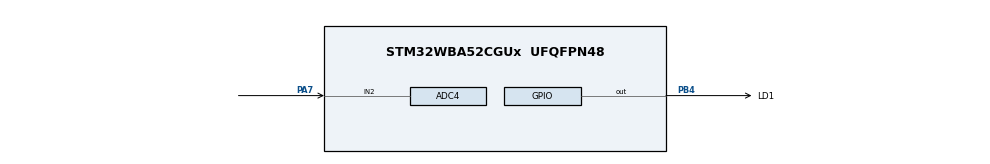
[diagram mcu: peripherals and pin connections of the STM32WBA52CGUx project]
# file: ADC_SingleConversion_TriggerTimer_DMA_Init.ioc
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ADC4.Channel-0\#ChannelRegularConversion=ADC_CHANNEL_2
ADC4.ClockPrescaler=ADC_CLOCK_ASYNC_DIV4
ADC4.DMAContinuousRequests=ENABLE
ADC4.ExternalTrigConv=ADC_EXTERNALTRIG_T1_TRGO2
ADC4.NbrOfConversionFlag=1
ADC4.Overrun=ADC_OVR_DATA_OVERWRITTEN
ADC4.Rank-0\#ChannelRegularConversion=1
ADC4.SamplingTime-0\#ChannelRegularConversion=ADC_SAMPLINGTIME_COMMON_1
ADC4.SelectedChannel=ADC_CHANNEL_2
CORTEX_M33_NS.userName=CORTEX_M33
GPDMA1.CIRCULARMODE_GPDMACH1=ENABLE
GPDMA1.DESTDATAWIDTH_GPDMACH1=DMA_DEST_DATAWIDTH_HALFWORD
GPDMA1.DESTINC_GPDMACH1=DMA_DINC_INCREMENTED
GPDMA1.IPHANDLE_GPDMACH1-SIMPLEREQUEST_GPDMACH1=__NULL
GPDMA1.REQUEST_GPDMACH1=GPDMA1_REQUEST_ADC4
GPDMA1.SRCDATAWIDTH_GPDMACH1=DMA_SRC_DATAWIDTH_HALFWORD
Mcu.Family=STM32WBA
Mcu.Name=STM32WBA52CGUx
Mcu.Package=UFQFPN48
NVIC.ADC4_IRQn=true\:0\:0\:false\:false\:false\:true\:true\:true
NVIC.GPDMA1_Channel1_IRQn=true\:0\:0\:false\:false\:false\:false\:true\:true
NVIC.PriorityGroup=NVIC_PRIORITYGROUP_4
OSC_IN.Mode=HSE-External-Oscillator
OSC_IN.Signal=RCC_OSC_IN
OSC_OUT.Mode=HSE-External-Oscillator
OSC_OUT.Signal=RCC_OSC_OUT
PA7.Mode=IN2
PA7.Signal=ADC4_IN2
PB4\ (NJTRST).GPIO_Label=LD1
PB4\ (NJTRST).PinState=GPIO_PIN_SET
PB4\ (NJTRST).Signal=GPIO_Output
ProjectManager.HeapSize=0x200
ProjectManager.StackSize=0x400
ProjectManager.TargetToolchain=EWARM V9.20
RCC.ADCCLockSelectionVirtual=RCC_ADCCLKSOURCE_HSI
RCC.ADCFreq_Value=16000000
RCC.AHB5CLKDivider=DIV4
RCC.AHBFreq_Value=100000000
RCC.APB1Freq_Value=100000000
RCC.APB1TimFreq_Value=100000000
RCC.APB2Freq_Value=100000000
RCC.APB2TimFreq_Value=100000000
RCC.CortexFreq_Value=12500000
RCC.HCLKFreq_Value=100000000
RCC.HSE_VALUE=32000000
RCC.HSI_VALUE=16000000
RCC.LSE_VALUE=32768
RCC.PLLM=4
RCC.PLLN=25
RCC.PLLSourceVirtual=RCC_PLLSOURCE_HSE
RCC.SYSCLKFreq_VALUE=100000000
RCC.SYSCLKSourceVirtual=RCC_SYSCLKSOURCE_PLLCLK
RCC.VCOOutputFreq_Value=200000000
TIM1.PeriodNoDither=tim_period
TIM1.Prescaler=tim_prescaler
TIM1.TIM_MasterOutputTrigger=TIM_TRGO_RESET
TIM1.TIM_MasterOutputTrigger2=TIM_TRGO2_UPDATE
VP_GPDMA1_VS_GPDMACH1.Mode=SIMPLEREQUEST_GPDMACH1
VP_ICACHE_VS_ICACHE.Mode=DirectMappedCache
VP_PWR_VS_SECSignals.Mode=Security/Privilege
VP_TIM1_VS_ClockSourceINT.Mode=Internal
board=custom

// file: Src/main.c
/* USER CODE BEGIN Header */
/**
  ******************************************************************************
  * @file    Examples_LL/ADC/ADC_SingleConversion_TriggerTimer_DMA_Init/Src/main.c
  * @author  MCD Application Team
  * @brief   This example describes how to use a ADC peripheral to perform
  *          a single ADC conversion of a channel, at each trigger event
  *          from timer.
  *          Conversion data is transferred by DMA into a table in RAM memory,
  *          indefinitely (circular mode).
  *          This example is based on the STM32WBAxx ADC LL API;
  *          Peripheral initialization done using LL unitary services functions.
  ******************************************************************************
  * @attention
  *
  * Copyright (c) 2023 STMicroelectronics.
  * All rights reserved.
  *
  * This software is licensed under terms that can be found in the LICENSE file
  * in the root directory of this software component.
  * If no LICENSE file comes with this software, it is provided AS-IS.
  *
  ******************************************************************************
  */
/* USER CODE END Header */
#include "main.h"

/* USER CODE BEGIN PD */

/* Definitions of ADC hardware constraints delays */
/* Note: Only ADC IP HW delays are defined in ADC LL driver driver,           */
/*       not timeout values:                                                  */
/*       Timeout values for ADC operations are dependent to device clock      */
/*       configuration (system clock versus ADC clock),                       */
/*       and therefore must be defined in user application.                   */
/*       Refer to @ref ADC_LL_EC_HW_DELAYS for description of ADC timeout     */
/*       values definition.                                                   */

  /* Timeout values for ADC operations. */
  /* (calibration, enable settling time, disable settling time, ...)          */
  /* Values defined to be higher than worst cases: low clock frequency,       */
  /* maximum prescalers.                                                      */
  /* Note: ADC channel configuration ready (ADC_CHANNEL_CONF_RDY_TIMEOUT_MS)  */
  /*       is added in CubeMx code section.                                   */
  /* Unit: ms                                                                 */
  #define ADC_CALIBRATION_TIMEOUT_MS       (   1UL)
  #define ADC_ENABLE_TIMEOUT_MS            (   1UL)
  #define ADC_DISABLE_TIMEOUT_MS           (   1UL)
  #define ADC_STOP_CONVERSION_TIMEOUT_MS   (   1UL)
  #define ADC_CONVERSION_TIMEOUT_MS        (4000UL)

  /* Delay between ADC end of calibration and ADC enable.                     */
  /* Delay estimation in CPU cycles: Case of ADC enable done                  */
  /* immediately after ADC calibration, ADC clock setting slow                */
  /* (LL_ADC_CLOCK_ASYNC_DIV32). Use a higher delay if ratio                  */
  /* (CPU clock / ADC clock) is above 32.                                     */
  #define ADC_DELAY_CALIB_ENABLE_CPU_CYCLES  (LL_ADC_DELAY_CALIB_ENABLE_ADC_CYCLES * 32)

/* Definitions of environment analog values */
  /* Value of analog reference voltage (Vref+), connected to analog voltage   */
  /* supply Vdda (unit: mV).                                                  */
  #define VDDA_APPLI                       (3300UL)

/* Definitions of data related to this example */
  /* Definition of ADCx conversions data table size */
  #define ADC_CONVERTED_DATA_BUFFER_SIZE   (  64UL)

  /* Init variable out of expected ADC conversion data range */
  #define VAR_CONVERTED_DATA_INIT_VALUE    (__LL_ADC_DIGITAL_SCALE(LL_ADC_RESOLUTION_12B) + 1)

  /* Parameters of time base (used as ADC conversion trigger) */
  /* Time base frequency (unit: Hz). With a timer 16 bits and time base       */
  /* freq max 32kHz, range is [min=1Hz, max=32kHz].                           */
  #define TIMER_FREQUENCY_HZ               (1000UL)
  /* Time base range frequency maximum (unit: Hz).*/
  /* With a timer 16 bits, minimum frequency will be 1/32000 times this value.*/
  #define TIMER_FREQUENCY_RANGE_MAX_HZ    (32000UL)

/* USER CODE END PD */

LL_DMA_LinkNodeTypeDef Node_GPDMA1_Channel1;

/* USER CODE BEGIN PV */

/* Variables for ADC conversion data */
__IO uint16_t uhADCxConvertedData[ADC_CONVERTED_DATA_BUFFER_SIZE]; /* ADC group regular conversion data (array of data) */

/* Variables for ADC conversion data computation to physical values */
uint16_t uhADCxConvertedData_Voltage_mVolt[ADC_CONVERTED_DATA_BUFFER_SIZE];  /* Value of voltage calculated from ADC conversion data (unit: mV) (array of data) */

/* Variable to report status of DMA transfer of ADC group regular conversions */
/*  0: DMA transfer is not completed                                          */
/*  1: DMA transfer is completed                                              */
/*  2: DMA transfer has not yet been started yet (initial state)              */
__IO uint8_t ubDmaTransferStatus = 2U; /* Variable set into DMA interruption callback */

/* USER CODE END PV */

void SystemClock_Config(void);
static void MX_GPDMA1_Init(void);
static void MX_GPIO_Init(void);
static void MX_ICACHE_Init(void);
static void MX_ADC4_Init(void);
static void MX_TIM1_Init(void);
/* USER CODE BEGIN PFP */

void ADC_Activate(void);
void LED_On(void);
void LED_Off(void);
void LED_Toggle(void);

/* USER CODE END PFP */

int main(void)
{
  /* USER CODE BEGIN 1 */
  uint32_t tmp_index;

  /* Initialize ADC group regular data buffer values */
  for (tmp_index = 0; tmp_index < ADC_CONVERTED_DATA_BUFFER_SIZE; tmp_index++)
  {
    uhADCxConvertedData[tmp_index] = VAR_CONVERTED_DATA_INIT_VALUE;
  }

  /* USER CODE END 1 */

  /* MCU Configuration--------------------------------------------------------*/

  /* Reset of all peripherals, Initializes the Flash interface and the Systick. */

  /* System interrupt init*/
  NVIC_SetPriorityGrouping(NVIC_PRIORITYGROUP_4);

  /* SysTick_IRQn interrupt configuration */
  NVIC_SetPriority(SysTick_IRQn, NVIC_EncodePriority(NVIC_GetPriorityGrouping(),15, 0));

  /* Enable PWR clock interface */

  LL_AHB4_GRP1_EnableClock(LL_AHB4_GRP1_PERIPH_PWR);

  /* Configure the system clock */
  SystemClock_Config();

  /* Initialize all configured peripherals */
  MX_GPDMA1_Init();
  MX_GPIO_Init();
  MX_ICACHE_Init();
  MX_ADC4_Init();
  MX_TIM1_Init();
  /* USER CODE BEGIN 2 */

  /* Activate ADC */
  /* Perform ADC activation procedure to make it ready to convert. */
  ADC_Activate();

  /* Start ADC group regular conversion */
  /* Note: ADC conversion will effectively start at timer trigger event */
  /* Note: Hardware constraint (refer to description of the functions         */
  /*       below):                                                            */
  /*       On this STM32 series, setting of this feature is conditioned to    */
  /*       ADC state:                                                         */
  /*       ADC must be enabled without conversion on going on group regular,  */
  /*       without ADC disable command on going.                              */
  /* Note: In this example, all these checks are not necessary but are        */
  /*       implemented anyway to show the best practice usages                */
  /*       corresponding to reference manual procedure.                       */
  /*       Software can be optimized by removing some of these checks, if     */
  /*       they are not relevant considering previous settings and actions    */
  /*       in user application.                                               */
  if ((LL_ADC_IsEnabled(ADC4) == 1)               &&
      (LL_ADC_IsDisableOngoing(ADC4) == 0)        &&
      (LL_ADC_REG_IsConversionOngoing(ADC4) == 0)   )
  {
    LL_ADC_REG_StartConversion(ADC4);
  }
  else
  {
    /* Error: ADC conversion start could not be performed */
    Error_Handler();
  }

  /* Start time base */
  LL_TIM_EnableCounter(TIM1);

  /* USER CODE END 2 */

  /* Infinite loop */
  /* USER CODE BEGIN WHILE */
  while (1)
  {
    /* ADC group regular status: toggle LED at buffer conversion completed */
    if(ubDmaTransferStatus == 1)
    {
      LED_On();
    }
    else
    {
      LED_Off();
    }

    /* Note: ADC group regular conversions data are stored into array         */
    /*       "uhADCxConvertedData"                                            */
    /*       (for debug: see variable content into watch window).             */

    /* Note: ADC conversion data are computed to physical values              */
    /*       into array "uhADCxConvertedData_Voltage_mVolt" using             */
    /*       ADC LL driver helper macro "__LL_ADC_CALC_DATA_TO_VOLTAGE()"     */
    /*       (for debug: see variable content with debugger)                  */
    /*       in IRQ handlers callback functions.                              */

    /* USER CODE END WHILE */

  }
}

void SystemClock_Config(void)
{
  LL_FLASH_SetLatency(LL_FLASH_LATENCY_3);
  while(LL_FLASH_GetLatency()!= LL_FLASH_LATENCY_3)
  {
  }

  LL_PWR_SetRegulVoltageScaling(LL_PWR_REGU_VOLTAGE_SCALE1);
  LL_RCC_HSE_Enable();

   /* Wait till HSE is ready */
  while(LL_RCC_HSE_IsReady() != 1)
  {
  }

  LL_RCC_HSI_Enable();

   /* Wait till HSI is ready */
  while(LL_RCC_HSI_IsReady() != 1)
  {
  }

  LL_RCC_HSI_SetCalibTrimming(16);
  LL_RCC_PLL1_ConfigDomain_SYS(LL_RCC_PLL1SOURCE_HSE, 4, 25, 2);
  LL_RCC_PLL1_EnableDomain_PLL1R();
  LL_RCC_PLL1_SetVCOInputRange(LL_RCC_PLLINPUTRANGE_8_16);
  LL_RCC_PLL1_Enable();

   /* Wait till PLL is ready */
  while(LL_RCC_PLL1_IsReady() != 1)
  {
  }

  LL_RCC_SetSysClkSource(LL_RCC_SYS_CLKSOURCE_PLL1R);

   /* Wait till System clock is ready */
  while(LL_RCC_GetSysClkSource() != LL_RCC_SYS_CLKSOURCE_STATUS_PLL1R)
  {
  }

  LL_RCC_SetAHBPrescaler(LL_RCC_SYSCLK_DIV_1);
  LL_RCC_SetAHB5Prescaler(LL_RCC_AHB5_DIV_4);
  LL_RCC_SetAPB1Prescaler(LL_RCC_APB1_DIV_1);
  LL_RCC_SetAPB2Prescaler(LL_RCC_APB2_DIV_1);
  LL_RCC_SetAPB7Prescaler(LL_RCC_APB7_DIV_1);

  LL_Init1msTick(100000000);

  LL_SetSystemCoreClock(100000000);
}

static void MX_ADC4_Init(void)
{

  LL_ADC_InitTypeDef ADC_InitStruct = {0};
  LL_ADC_REG_InitTypeDef ADC_REG_InitStruct = {0};

  LL_GPIO_InitTypeDef GPIO_InitStruct = {0};
  LL_DMA_InitNodeTypeDef NodeConfig = {0};
  LL_DMA_InitLinkedListTypeDef DMA_InitLinkedListStruct = {0};

  LL_RCC_SetADCClockSource(LL_RCC_ADC_CLKSOURCE_HSI);

  /* Peripheral clock enable */
  LL_AHB4_GRP1_EnableClock(LL_AHB4_GRP1_PERIPH_ADC4);

  LL_AHB2_GRP1_EnableClock(LL_AHB2_GRP1_PERIPH_GPIOA);
  /**ADC4 GPIO Configuration
  PA7   ------> ADC4_IN2
  */
  GPIO_InitStruct.Pin = LL_GPIO_PIN_7;
  GPIO_InitStruct.Mode = LL_GPIO_MODE_ANALOG;
  GPIO_InitStruct.Pull = LL_GPIO_PULL_NO;
  LL_GPIO_Init(GPIOA, &GPIO_InitStruct);

  /* ADC4 DMA Init */

  /* GPDMA1_REQUEST_ADC4 Init */
  NodeConfig.DestAllocatedPort = LL_DMA_DEST_ALLOCATED_PORT0;
  NodeConfig.DestHWordExchange = LL_DMA_DEST_HALFWORD_PRESERVE;
  NodeConfig.DestByteExchange = LL_DMA_DEST_BYTE_PRESERVE;
  NodeConfig.DestBurstLength = 1;
  NodeConfig.DestIncMode = LL_DMA_DEST_INCREMENT;
  NodeConfig.DestDataWidth = LL_DMA_DEST_DATAWIDTH_HALFWORD;
  NodeConfig.SrcAllocatedPort = LL_DMA_SRC_ALLOCATED_PORT0;
  NodeConfig.SrcByteExchange = LL_DMA_SRC_BYTE_PRESERVE;
  NodeConfig.DataAlignment = LL_DMA_DATA_ALIGN_ZEROPADD;
  NodeConfig.SrcBurstLength = 1;
  NodeConfig.SrcIncMode = LL_DMA_SRC_FIXED;
  NodeConfig.SrcDataWidth = LL_DMA_SRC_DATAWIDTH_HALFWORD;
  NodeConfig.TransferEventMode = LL_DMA_TCEM_BLK_TRANSFER;
  NodeConfig.TriggerPolarity = LL_DMA_TRIG_POLARITY_MASKED;
  NodeConfig.BlkHWRequest = LL_DMA_HWREQUEST_SINGLEBURST;
  NodeConfig.Direction = LL_DMA_DIRECTION_PERIPH_TO_MEMORY;
  NodeConfig.Request = LL_GPDMA1_REQUEST_ADC4;
  NodeConfig.UpdateRegisters = (LL_DMA_UPDATE_CTR1 | LL_DMA_UPDATE_CTR2 | LL_DMA_UPDATE_CBR1 | LL_DMA_UPDATE_CSAR | LL_DMA_UPDATE_CDAR | LL_DMA_UPDATE_CLLR);
  NodeConfig.NodeType = LL_DMA_GPDMA_LINEAR_NODE;
  LL_DMA_CreateLinkNode(&NodeConfig, &Node_GPDMA1_Channel1);

  LL_DMA_ConnectLinkNode(&Node_GPDMA1_Channel1, LL_DMA_CLLR_OFFSET5, &Node_GPDMA1_Channel1, LL_DMA_CLLR_OFFSET5);

  /* Next function call is commented because it will not compile as is. The Node structure address has to be cast to an unsigned int (uint32_t)pNode_DMAxCHy */
  /*

  */
  LL_DMA_SetLinkedListBaseAddr(GPDMA1, LL_DMA_CHANNEL_1, (uint32_t)&Node_GPDMA1_Channel1);

  DMA_InitLinkedListStruct.Priority = LL_DMA_LOW_PRIORITY_LOW_WEIGHT;
  DMA_InitLinkedListStruct.LinkStepMode = LL_DMA_LSM_FULL_EXECUTION;
  DMA_InitLinkedListStruct.LinkAllocatedPort = LL_DMA_LINK_ALLOCATED_PORT0;
  DMA_InitLinkedListStruct.TransferEventMode = LL_DMA_TCEM_BLK_TRANSFER;
  LL_DMA_List_Init(GPDMA1, LL_DMA_CHANNEL_1, &DMA_InitLinkedListStruct);

  /* ADC4 interrupt Init */
  NVIC_SetPriority(ADC4_IRQn, NVIC_EncodePriority(NVIC_GetPriorityGrouping(),0, 0));
  NVIC_EnableIRQ(ADC4_IRQn);

  /* USER CODE BEGIN ADC4_Init 1 */
  LL_DMA_SetBlkDataLength(GPDMA1,
                          LL_DMA_CHANNEL_1,
                          ADC_CONVERTED_DATA_BUFFER_SIZE);
  LL_DMA_ConfigAddresses(GPDMA1,
                         LL_DMA_CHANNEL_1,
                         LL_ADC_DMA_GetRegAddr(ADC4, LL_ADC_DMA_REG_REGULAR_DATA),
                         (uint32_t)&uhADCxConvertedData);

  /* Enable GPDMA1 interrupts complete/error */
  LL_DMA_EnableIT_TC(GPDMA1, LL_DMA_CHANNEL_1);
  LL_DMA_EnableIT_HT(GPDMA1, LL_DMA_CHANNEL_1);
  LL_DMA_EnableIT_DTE(GPDMA1, LL_DMA_CHANNEL_1);

  LL_DMA_SetLinkedListAddrOffset(GPDMA1, LL_DMA_CHANNEL_1, LL_DMA_CLLR_OFFSET5);

  LL_DMA_EnableChannel(GPDMA1, LL_DMA_CHANNEL_1);
  /* USER CODE END ADC4_Init 1 */

  /** Common config
  */
  LL_ADC_SetTriggerFrequencyMode(ADC4, LL_ADC_TRIGGER_FREQ_LOW);
  ADC_InitStruct.Resolution = LL_ADC_RESOLUTION_12B;
  ADC_InitStruct.DataAlignment = LL_ADC_DATA_ALIGN_RIGHT;
  LL_ADC_Init(ADC4, &ADC_InitStruct);
  LL_ADC_REG_SetSequencerConfigurable(ADC4, LL_ADC_REG_SEQ_CONFIGURABLE);
  ADC_REG_InitStruct.TriggerSource = LL_ADC_REG_TRIG_EXT_TIM1_TRGO2;
  ADC_REG_InitStruct.SequencerLength = LL_ADC_REG_SEQ_SCAN_DISABLE;
  ADC_REG_InitStruct.SequencerDiscont = LL_ADC_REG_SEQ_DISCONT_DISABLE;
  ADC_REG_InitStruct.ContinuousMode = LL_ADC_REG_CONV_SINGLE;
  ADC_REG_InitStruct.DMATransfer = LL_ADC_REG_DMA_TRANSFER_UNLIMITED;
  ADC_REG_InitStruct.Overrun = LL_ADC_REG_OVR_DATA_OVERWRITTEN;
  LL_ADC_REG_Init(ADC4, &ADC_REG_InitStruct);
  LL_ADC_SetLPModeAutoPowerOff(ADC4, DISABLE);
  LL_ADC_SetLPModeAutonomousDPD(ADC4, LL_ADC_LP_AUTONOMOUS_DPD_DISABLE);
  LL_ADC_SetSamplingTimeCommonChannels(ADC4, LL_ADC_SAMPLINGTIME_COMMON_1, LL_ADC_SAMPLINGTIME_1CYCLE_5);
  LL_ADC_SetSamplingTimeCommonChannels(ADC4, LL_ADC_SAMPLINGTIME_COMMON_2, LL_ADC_SAMPLINGTIME_1CYCLE_5);
  LL_ADC_REG_SetTriggerEdge(ADC4, LL_ADC_REG_TRIG_EXT_RISING);

  /* Enable ADC internal voltage regulator */
  LL_ADC_EnableInternalRegulator(ADC4);
  /* Delay for ADC internal voltage regulator stabilization. */
  /* Compute number of CPU cycles to wait for, from delay in us. */
  /* Note: Variable divided by 2 to compensate partially */
  /* CPU processing cycles (depends on compilation optimization). */
  /* Note: If system core clock frequency is below 200kHz, wait time */
  /* is only a few CPU processing cycles. */
  uint32_t wait_loop_index;
  wait_loop_index = ((LL_ADC_DELAY_INTERNAL_REGUL_STAB_US * (SystemCoreClock / (100000 * 2))) / 10);
  while(wait_loop_index != 0)
  {
    wait_loop_index--;
  }

  /** Configure Regular Channel
  */
  LL_ADC_REG_SetSequencerRanks(ADC4, LL_ADC_REG_RANK_1, LL_ADC_CHANNEL_2);
  LL_ADC_SetChannelSamplingTime(ADC4, LL_ADC_CHANNEL_2, LL_ADC_SAMPLINGTIME_COMMON_1);
  /* USER CODE BEGIN ADC4_Init 2 */

  /* Configuration of ADC interruptions */
  /* Enable interruption ADC group regular overrun */
  LL_ADC_EnableIT_OVR(ADC4);

  /* USER CODE END ADC4_Init 2 */

}

static void MX_GPDMA1_Init(void)
{

  /* Peripheral clock enable */
  LL_AHB1_GRP1_EnableClock(LL_AHB1_GRP1_PERIPH_GPDMA1);

  /* GPDMA1 interrupt Init */
  NVIC_SetPriority(GPDMA1_Channel1_IRQn, NVIC_EncodePriority(NVIC_GetPriorityGrouping(),0, 0));
  NVIC_EnableIRQ(GPDMA1_Channel1_IRQn);

}

static void MX_ICACHE_Init(void)
{

  /** Enable instruction cache in 1-way (direct mapped cache)
  */
  LL_ICACHE_SetMode(LL_ICACHE_1WAY);
  LL_ICACHE_Enable();

}

static void MX_TIM1_Init(void)
{

  /* USER CODE BEGIN TIM1_Init 0 */
  uint32_t tim_prescaler;
  uint32_t tim_period;
  /* USER CODE END TIM1_Init 0 */

  LL_TIM_InitTypeDef TIM_InitStruct = {0};

  /* Peripheral clock enable */
  LL_APB2_GRP1_EnableClock(LL_APB2_GRP1_PERIPH_TIM1);

  /* USER CODE BEGIN TIM1_Init 1 */
  /* Set timer prescaler value (timer frequency) */
  /* Note: Value TIMER_FREQUENCY_RANGE_MAX_HZ with factor 2 to have a minimum
           timer resolution */
  tim_prescaler = __LL_TIM_CALC_PSC(SystemCoreClock, TIMER_FREQUENCY_RANGE_MAX_HZ * 2);

  /* Set timer period value (time base frequency) */
  tim_period = __LL_TIM_CALC_ARR(SystemCoreClock, tim_prescaler, TIMER_FREQUENCY_HZ);

  /* USER CODE END TIM1_Init 1 */
  TIM_InitStruct.Prescaler = tim_prescaler;
  TIM_InitStruct.CounterMode = LL_TIM_COUNTERMODE_UP;
  TIM_InitStruct.Autoreload = tim_period;
  TIM_InitStruct.ClockDivision = LL_TIM_CLOCKDIVISION_DIV1;
  TIM_InitStruct.RepetitionCounter = 0;
  LL_TIM_Init(TIM1, &TIM_InitStruct);
  LL_TIM_DisableARRPreload(TIM1);
  LL_TIM_SetClockSource(TIM1, LL_TIM_CLOCKSOURCE_INTERNAL);
  LL_TIM_SetTriggerOutput(TIM1, LL_TIM_TRGO_RESET);
  LL_TIM_SetTriggerOutput2(TIM1, LL_TIM_TRGO2_UPDATE);
  LL_TIM_DisableMasterSlaveMode(TIM1);

}

static void MX_GPIO_Init(void)
{
  LL_GPIO_InitTypeDef GPIO_InitStruct = {0};

  /* GPIO Ports Clock Enable */
  LL_AHB2_GRP1_EnableClock(LL_AHB2_GRP1_PERIPH_GPIOA);
  LL_AHB2_GRP1_EnableClock(LL_AHB2_GRP1_PERIPH_GPIOB);

  /**/
  LL_GPIO_SetOutputPin(LD1_GPIO_Port, LD1_Pin);

  /**/
  GPIO_InitStruct.Pin = LD1_Pin;
  GPIO_InitStruct.Mode = LL_GPIO_MODE_OUTPUT;
  GPIO_InitStruct.Speed = LL_GPIO_SPEED_FREQ_LOW;
  GPIO_InitStruct.OutputType = LL_GPIO_OUTPUT_PUSHPULL;
  GPIO_InitStruct.Pull = LL_GPIO_PULL_NO;
  LL_GPIO_Init(LD1_GPIO_Port, &GPIO_InitStruct);

}

/* USER CODE BEGIN 4 */

/**
  * @brief  Perform ADC activation procedure to make it ready to convert
  *         (ADC instance: ADC4).
  * @param  None
  * @retval None
  */
void ADC_Activate(void)
{
  __IO uint32_t wait_loop_index = 0U;
  __IO uint32_t backup_setting_adc_dma_transfer = 0U;
  #if (USE_TIMEOUT == 1)
  uint32_t Timeout = 0U; /* Variable used for timeout management */
  #endif /* USE_TIMEOUT */

  /*## Operation on ADC hierarchical scope: ADC instance #####################*/

  /* Note: Hardware constraint (refer to description of the functions         */
  /*       below):                                                            */
  /*       On this STM32 series, setting of these features is conditioned to  */
  /*       ADC state:                                                         */
  /*       ADC must be disabled.                                              */
  /* Note: In this example, all these checks are not necessary but are        */
  /*       implemented anyway to show the best practice usages                */
  /*       corresponding to reference manual procedure.                       */
  /*       Software can be optimized by removing some of these checks, if     */
  /*       they are not relevant considering previous settings and actions    */
  /*       in user application.                                               */
  if (LL_ADC_IsEnabled(ADC4) == 0)
  {
    /* Enable ADC internal voltage regulator */
    LL_ADC_EnableInternalRegulator(ADC4);

    /* Delay for ADC internal voltage regulator stabilization.                */
    /* Compute number of CPU cycles to wait for, from delay in us.            */
    /* Note: Variable divided by 2 to compensate partially                    */
    /*       CPU processing cycles (depends on compilation optimization).     */
    /* Note: If system core clock frequency is below 200kHz, wait time        */
    /*       is only a few CPU processing cycles.                             */
    wait_loop_index = ((LL_ADC_DELAY_INTERNAL_REGUL_STAB_US * (SystemCoreClock / (100000 * 2))) / 10);
    while(wait_loop_index != 0)
    {
      wait_loop_index--;
    }

    /* Disable ADC DMA transfer request during calibration */
    /* Note: Specificity of this STM32 series: Calibration factor is           */
    /*       available in data register and also transferred by DMA.           */
    /*       To not insert ADC calibration factor among ADC conversion data   */
    /*       in DMA destination address, DMA transfer must be disabled during */
    /*       calibration.                                                     */
    backup_setting_adc_dma_transfer = LL_ADC_REG_GetDMATransfer(ADC4);
    LL_ADC_REG_SetDMATransfer(ADC4, LL_ADC_REG_DMA_TRANSFER_NONE);

    /* Run ADC self calibration */
    LL_ADC_StartCalibration(ADC4);

    /* Poll for ADC effectively calibrated */
    #if (USE_TIMEOUT == 1)
    Timeout = ADC_CALIBRATION_TIMEOUT_MS;
    #endif /* USE_TIMEOUT */

    while (LL_ADC_IsCalibrationOnGoing(ADC4) != 0)
    {
    #if (USE_TIMEOUT == 1)
      /* Check Systick counter flag to decrement the time-out value */
      if (LL_SYSTICK_IsActiveCounterFlag())
      {
        if(Timeout-- == 0)
        {
          /* Error: Time-out */
          Error_Handler();
        }
      }
    #endif /* USE_TIMEOUT */
    }

    /* Restore ADC DMA transfer request after calibration */
    LL_ADC_REG_SetDMATransfer(ADC4, backup_setting_adc_dma_transfer);

    /* Delay between ADC end of calibration and ADC enable.                   */
    /* Note: Variable divided by 2 to compensate partially                    */
    /*       CPU processing cycles (depends on compilation optimization).     */
    wait_loop_index = (ADC_DELAY_CALIB_ENABLE_CPU_CYCLES >> 1);
    while(wait_loop_index != 0)
    {
      wait_loop_index--;
    }

    /* Enable ADC */
    LL_ADC_Enable(ADC4);

    /* Poll for ADC ready to convert */
    #if (USE_TIMEOUT == 1)
    Timeout = ADC_ENABLE_TIMEOUT_MS;
    #endif /* USE_TIMEOUT */

    while (LL_ADC_IsActiveFlag_ADRDY(ADC4) == 0)
    {
    #if (USE_TIMEOUT == 1)
      /* Check Systick counter flag to decrement the time-out value */
      if (LL_SYSTICK_IsActiveCounterFlag())
      {
        if(Timeout-- == 0)
        {
          /* Error: Time-out */
          Error_Handler();
        }
      }
    #endif /* USE_TIMEOUT */
    }

    /* Note: ADC flag ADRDY is not cleared here to be able to check ADC       */
    /*       status afterwards.                                               */
    /*       This flag should be cleared at ADC Deactivation, before a new    */
    /*       ADC activation, using function "LL_ADC_ClearFlag_ADRDY()".       */
  }

  /*## Operation on ADC hierarchical scope: ADC group regular ################*/
  /* Note: No operation on ADC group regular performed here.                  */
  /*       ADC group regular conversions to be performed after this function  */
  /*       using function:                                                    */
  /*       "LL_ADC_REG_StartConversion();"                                    */

  /*## Operation on ADC hierarchical scope: ADC group injected ###############*/
  /* Note: Feature not available on this STM32 series */

}

/**
  * @brief  Turn-on LD1.
  * @param  None
  * @retval None
  */
void LED_On(void)
{
  /* Turn LED on */
  LL_GPIO_ResetOutputPin(LD1_GPIO_Port, LD1_Pin);
}

/**
  * @brief  Turn-off LD1.
  * @param  None
  * @retval None
  */
void LED_Off(void)
{
  /* Turn LED off */
  LL_GPIO_SetOutputPin(LD1_GPIO_Port, LD1_Pin);
}

/**
  * @brief  Toggle LD1.
  * @param  None
  * @retval None
  */
void LED_Toggle(void)
{
  /* Toggle LED */
  LL_GPIO_TogglePin(LD1_GPIO_Port, LD1_Pin);
}

/******************************************************************************/
/*   USER IRQ HANDLER TREATMENT                                               */
/******************************************************************************/

/**
  * @brief  DMA transfer complete callback
  * @note   This function is executed when the transfer complete interrupt
  *         is generated
  * @retval None
  */
void AdcDmaTransferComplete_Callback()
{
  uint32_t tmp_index;

  /* Data integrity check: Ensure that 2nd half of buffer has not yet been
     overwritten by DMA transfer: end of 1st half of buffer should equal to
     init value */
  if (uhADCxConvertedData[ADC_CONVERTED_DATA_BUFFER_SIZE/2 - 1] != VAR_CONVERTED_DATA_INIT_VALUE)
  {
    /* Error: buffer overwritten */
    /* Note: For debug purpose, if program is halted with a breakpoint then
             this error will be raised (due to ADC and DMA continuing to operate
             in background).
             To not block debug of this example, replace error handler by
             dummy LED toggle. */
    /* Error_Handler(); */
    LED_Toggle();
  }

  /* Computation of ADC conversions raw data to physical values
     using LL ADC driver helper macro. */
  /* Management of the 2nd half of buffer */
  for (tmp_index = (ADC_CONVERTED_DATA_BUFFER_SIZE/2); tmp_index < ADC_CONVERTED_DATA_BUFFER_SIZE; tmp_index++)
  {
    uhADCxConvertedData[tmp_index] = LL_ADC_REG_ReadConversionData32(ADC4);
    uhADCxConvertedData_Voltage_mVolt[tmp_index] = __LL_ADC_CALC_DATA_TO_VOLTAGE(VDDA_APPLI, uhADCxConvertedData[tmp_index], LL_ADC_RESOLUTION_12B);
  }

  /* Set half-buffer last data to init value for further data integrity check */
  uhADCxConvertedData[tmp_index - 1] = VAR_CONVERTED_DATA_INIT_VALUE;

  /* Update status variable of DMA transfer */
  ubDmaTransferStatus = 1;
}

/**
  * @brief  DMA half transfer callback
  * @note   This function is executed when the half transfer interrupt
  *         is generated
  * @retval None
  */
void AdcDmaTransferHalf_Callback()
{
  uint32_t tmp_index;

  /* Data integrity check: Ensure that 1st half of buffer has not yet been
     overwritten by DMA transfer: end of 2nd half of buffer should equal to
     init value */
  if (uhADCxConvertedData[ADC_CONVERTED_DATA_BUFFER_SIZE - 1] != VAR_CONVERTED_DATA_INIT_VALUE)
  {
    /* Error: buffer overwritten */
    /* Note: For debug purpose, if program is halted with a breakpoint then
             this error will be raised (due to ADC and DMA continuing to operate
             in background).
             To not block debug of this example, replace error handler by
             dummy LED toggle. */
    /* Error_Handler(); */
    LED_Toggle();
  }

  /* Computation of ADC conversions raw data to physical values
     using LL ADC driver helper macro. */
  /* Management of the 1st half of buffer */
  for (tmp_index = 0; tmp_index < (ADC_CONVERTED_DATA_BUFFER_SIZE/2); tmp_index++)
  {
    uhADCxConvertedData[tmp_index] = LL_ADC_REG_ReadConversionData32(ADC4);
    uhADCxConvertedData_Voltage_mVolt[tmp_index] = __LL_ADC_CALC_DATA_TO_VOLTAGE(VDDA_APPLI, uhADCxConvertedData[tmp_index], LL_ADC_RESOLUTION_12B);
  }

  /* Set half-buffer last data to init value for further data integrity check */
  uhADCxConvertedData[tmp_index - 1] = VAR_CONVERTED_DATA_INIT_VALUE;

  /* Update status variable of DMA transfer */
  ubDmaTransferStatus = 0;
}

/**
  * @brief  DMA transfer error callback
  * @note   This function is executed when the transfer error interrupt
  *         is generated during DMA transfer
  * @retval None
  */
void AdcDmaTransferError_Callback()
{
  if(ubDmaTransferStatus == 1)
  {
    /* Update status variable of DMA transfer */
    ubDmaTransferStatus = 0;
  }

  /* Error detected during DMA transfer */
  Error_Handler();
}

/**
  * @brief  ADC group regular overrun interruption callback
  * @note   This function is executed when ADC group regular
  *         overrun error occurs.
  * @retval None
  */
void AdcGrpRegularOverrunError_Callback(void)
{
  /* Note: Disable ADC interruption that caused this error before entering in
           infinite loop below. */

  /* In case of error due to overrun: Disable ADC group regular overrun interruption */
  LL_ADC_DisableIT_OVR(ADC4);

  /* Error reporting */
  Error_Handler();
}

/* USER CODE END 4 */

void Error_Handler(void)
{
  /* USER CODE BEGIN Error_Handler_Debug */
  /* User can add his own implementation to report the HAL error return state */

  /* Turn on LED and remain in infinite loop */
  while (1)
  {
    LED_On();
  }
  /* USER CODE END Error_Handler_Debug */
}
